# CTRL_MODULE_CORE register map
Vendor: Texas Instruments
Registers are 32-bit, access per field, reset 0x0 unless marked. A register's access mark holds for its fields unless they carry their own. Offsets are as the file gives them; [hi:lo] are bit positions; {n}, {i} and the like mark numbered series; 'fields as' and 'values as' point back to an identical list.

## CTRL_MODULE_CORE (part 2 of 12)
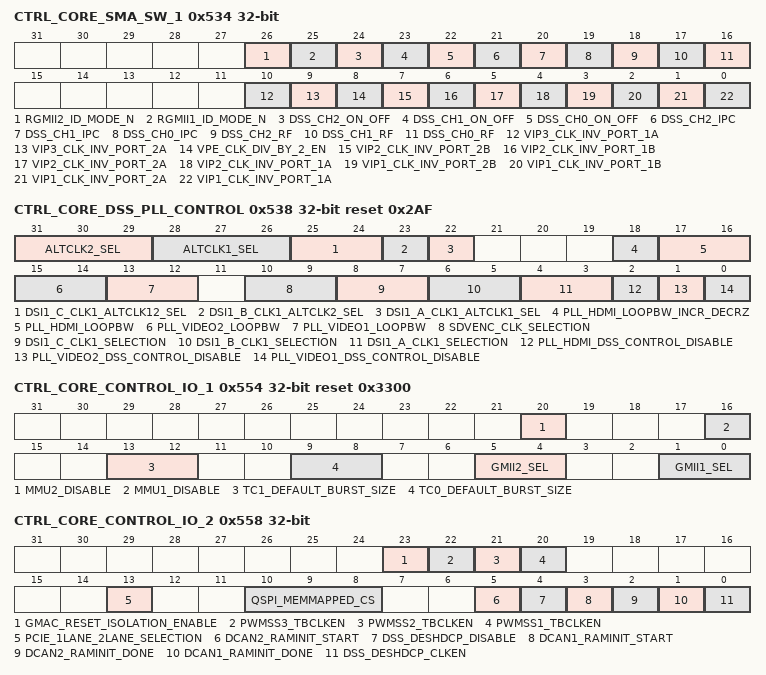
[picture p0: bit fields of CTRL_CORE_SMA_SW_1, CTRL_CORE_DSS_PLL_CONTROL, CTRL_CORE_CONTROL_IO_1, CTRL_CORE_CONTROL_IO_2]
0x534 CTRL_CORE_SMA_SW_1 — OCP Spare Register
  [26] RGMII2_ID_MODE_N rw — Ethernet RGMII port 2 internal delay on transmit 0x0: Internal delay enabled 0x1: Internal delay disabled
  [25] RGMII1_ID_MODE_N rw — Ethernet RGMII port 1 internal delay on transmit 0x0: Internal delay enabled 0x1: Internal delay disabled
  [24] DSS_CH2_ON_OFF rw — DSS Channel 2 Pixel clock control On/Off 0x0: HSYNC and VSYNC are driven on opposite edges of pixel clock than pixel data 0x1: HSYNC and VSYNC are driven according to bit DSS_CH2_RF
  [23] DSS_CH1_ON_OFF rw — DSS Channel 1 Pixel clock control On/Off 0x0: HSYNC and VSYNC are driven on opposite edges of pixel clock than pixel data 0x1: HSYNC and VSYNC are driven according to bit DSS_CH1_RF
  [22] DSS_CH0_ON_OFF rw — DSS Channel 0 Pixel clock control On/Off 0x0: HSYNC and VSYNC are driven on opposite edges of pixel clock than pixel data 0x1: HSYNC and VSYNC are driven according to bit DSS_CH0_RF
  [21] DSS_CH2_IPC rw — DSS Channel 2 IPC control 0x0: Data is driven on the LCD data lines on the rising edge of the pixel clock 0x1: Data is driven on the LCD data lines on the falling edge of the pixel clock
  [20] DSS_CH1_IPC rw — DSS Channel 1 IPC control 0x0: Data is driven on the LCD data lines on the rising edge of the pixel clock 0x1: Data is driven on the LCD data lines on the falling edge of the pixel clock
  [19] DSS_CH0_IPC rw — DSS Channel 0 IPC control 0x0: Data is driven on the LCD data lines on the rising edge of the pixel clock 0x1: Data is driven on the LCD data lines on the falling edge of the pixel clock
  [18] DSS_CH2_RF rw — DSS Channel 2 Rise/Fall control 0x0: HSYNC and VSYNC are driven on falling edge of pixel clock (if bit DSS_CH2_ON_OFF set to 1) 0x1: HSYNC and VSYNC are driven on rising edge of pixel clock (if bit DSS_CH2_ON_OFF set to 1)
  [17] DSS_CH1_RF rw — DSS Channel 1 Rise/Fall control 0x0: HSYNC and VSYNC are driven on falling edge of pixel clock (if bit DSS_CH1_ON_OFF set to 1) 0x1: HSYNC and VSYNC are driven on rising edge of pixel clock (if bit DSS_CH1_ON_OFF set to 1)
  [16] DSS_CH0_RF rw — DSS Channel 0 Rise/Fall control 0x0: HSYNC and VSYNC are driven on falling edge of pixel clock (if bit DSS_CH0_ON_OFF set to 1) 0x1: HSYNC and VSYNC are driven on rising edge of pixel clock (if bit DSS_CH0_ON_OFF set to 1)
  [10] VIP3_CLK_INV_PORT_1A rw — VIP3 Slice 1 Clock inversion for Port A enable 0x0: clock inversion is disabled 0x1: clock inversion is enabled
  [9] VIP3_CLK_INV_PORT_2A rw — VIP3 Slice 0 Clock inversion for Port A enable 0x0: clock inversion is disabled 0x1: clock inversion is enabled
  [8] VPE_CLK_DIV_BY_2_EN rw — Selects alternative clock source for VPE. 0x0: Default clock source from DPLL_CORE is selected 0x1: Alternative clock source from DPLL_VIDEO1 is selected
  [7] VIP2_CLK_INV_PORT_2B rw — VIP2 Slice 1 Clock inversion for Port B enable 0x0: clock inversion is disabled 0x1: clock inversion is enabled
  [6] VIP2_CLK_INV_PORT_1B rw — VIP2 Slice 0 Clock inversion for Port B enable 0x0: clock inversion is disabled 0x1: clock inversion is enabled
  [5] VIP2_CLK_INV_PORT_2A rw — VIP2 Slice 1 Clock inversion for Port A enable 0x0: clock inversion is disabled 0x1: clock inversion is enabled
  [4] VIP2_CLK_INV_PORT_1A rw — VIP2 Slice 0 Clock inversion for Port A enable 0x0: clock inversion is disabled 0x1: clock inversion is enabled
  [3] VIP1_CLK_INV_PORT_2B rw — VIP1 Slice 1 Clock inversion for Port B enable 0x0: clock inversion is disabled 0x1: clock inversion is enabled
  [2] VIP1_CLK_INV_PORT_1B rw — VIP1 Slice 0 Clock inversion for Port B enable 0x0: clock inversion is disabled 0x1: clock inversion is enabled
  [1] VIP1_CLK_INV_PORT_2A rw — VIP1 Slice 1 Clock inversion for Port A enable 0x0: clock inversion is disabled 0x1: clock inversion is enabled
  [0] VIP1_CLK_INV_PORT_1A rw — VIP1 Slice 0 Clock inversion for Port A enable 0x0: clock inversion is disabled 0x1: clock inversion is enabled
0x538 CTRL_CORE_DSS_PLL_CONTROL rw reset 0x2AF — DSS PLLs Mux control register
  [31:29] ALTCLK2_SEL — Alternative clock selection for DSI1_B_CLK1, DSI1_C_CLK1 or both based on fields DSI1_B_CLK1_ALTCLK2_SEL and DSI1_C_CLK1_ALTCLK12_SEL. 0x0: wakeup0 pin 0x1: wakeup1 pin 0x2: vin1a_clk pin 0x3: vin1b_clk pin 0x4: DPLL_PCIE_REF 0x5: Reserved 0x6: DPLL_SATA 0x7: Reserved
  [28:26] ALTCLK1_SEL — Alternative clock selection for DSI1_A_CLK1, DSI1_C_CLK1 or both based on fields DSI1_A_CLK1_ALTCLK1_SEL and DSI1_C_CLK1_ALTCLK12_SEL. 0x0: wakeup0 pin 0x1: wakeup1 pin 0x2: vin1a_clk pin 0x3: vin1b_clk pin 0x4: DPLL_PCIE_REF 0x5: Reserved 0x6: DPLL_SATA 0x7: Reserved
  [25:24] DSI1_C_CLK1_ALTCLK12_SEL — DSI1_C_CLK1 alternative clock selection 0x0: Clock selection based on DSI1_C_CLK1_SELECTION 0x1: Clock selection based on ALTCLK1_SEL 0x2: Clock selection based on ALTCLK2_SEL 0x3: Reserved
  [23] DSI1_B_CLK1_ALTCLK2_SEL — DSI1_B_CLK1 alternative clock selection 0x0: Clock selection based on DSI1_B_CLK1_SELECTION 0x1: Clock selection based on ALTCLK2_SEL
  [22] DSI1_A_CLK1_ALTCLK1_SEL — DSI1_A_CLK1 alternative clock selection 0x0: Clock selection based on DSI1_A_CLK1_SELECTION 0x1: Clock selection based on ALTCLK1_SEL
  [18] PLL_HDMI_LOOPBW_INCR_DECRZ — 0x0: Decrease DPLL_HDMI loop bandwidth 0x1: Increase DPLL_HDMI loop bandwidth
  [17:16] PLL_HDMI_LOOPBW — DPLL_HDMI loop bandwidth mode If PLL_HDMI_LOOPBW_INCR_DECRZ = 0x0: 0x0: 1x Mode (Loop BW is REF_CLK/50) 0x1: 0.5x Mode (Loop BW is REF_CLK/100) 0x2: 0.25x Mode (Loop BW is REF_CLK/200) 0x3: 0.125x Mode (Loop BW is REF_CLK/400) If PLL_HDMI_LOOPBW_INCR_DECRZ = 0x1: 0x0: 1x Mode (Loop BW is REF_CLK/50) 0x1: 2x Mode (Loop BW is REF_CLK/25) 0x2: Reserved 0x3: Reserved
  [15:14] PLL_VIDEO2_LOOPBW — DPLL_VIDEO2 loop bandwidth mode 0x0: 1x Mode (Loop BW is REF_CLK/50) 0x1: 0.5x Mode (Loop BW is REF_CLK/100) 0x2: 0.25x Mode (Loop BW is REF_CLK/200) 0x3: 0.125x Mode (Loop BW is REF_CLK/400)
  [13:12] PLL_VIDEO1_LOOPBW — DPLL_VIDEO1 loop bandwidth mode 0x0: 1x Mode (Loop BW is REF_CLK/50) 0x1: 0.5x Mode (Loop BW is REF_CLK/100) 0x2: 0.25x Mode (Loop BW is REF_CLK/200) 0x3: 0.125x Mode (Loop BW is REF_CLK/400)
  [10:9] SDVENC_CLK_SELECTION — SDVENC_CLK mux configuration 0x0: HDMI_CLK 0x1: DPLL_VIDEO1_HSDIVIDER_clkout3
  [8:7] DSI1_C_CLK1_SELECTION — DSI1_C_CLK1 mux configuration 0x0: DPLL_VIDEO2 0x1: DPLL_VIDEO1 0x2: DPLL_HDMI
  [6:5] DSI1_B_CLK1_SELECTION — DSI1_B_CLK1 mux configuration 0x0: DPLL_VIDEO1 0x1: DPLL_VIDEO2 0x2: DPLL_HDMI 0x3: DPLL_ABE
  [4:3] DSI1_A_CLK1_SELECTION — DSI1_A_CLK1 mux configuration 0x0: DPLL_VIDEO1 0x1: DPLL_HDMI
  [2] PLL_HDMI_DSS_CONTROL_DISABLE — HDMI PLL disable 0x0: PLL enabled 0x1: PLL disabled
  [1] PLL_VIDEO2_DSS_CONTROL_DISABLE — VIDEO2 PLL disable 0x0: PLL enabled 0x1: PLL disabled
  [0] PLL_VIDEO1_DSS_CONTROL_DISABLE — VIDEO1 PLL disable 0x0: PLL enabled 0x1: PLL disabled
0x540 CTRL_CORE_MMR_LOCK_1 rw reset 0x1A1C8144 — Register to lock memory region starting at address offset 0x0000 0100 and ending at address offset 0x0000 079F
  [31:0] MMR_LOCK_1 — Lock value for region 0x0000 0100 to 0x0000 079F 0x1A1C8144 = lock value 0x2FF1AC2B = unlock value
0x544 CTRL_CORE_MMR_LOCK_2 rw reset 0xFDF45530 — Register to lock memory region starting at address offset 0x0000 07A0 and ending at address offset 0x0000 0D9F
  [31:0] MMR_LOCK_2 — Lock value for region 0x0000 07A0 to 0x0000 0D9F 0xFDF45530 = lock value 0xF757FDC0 = unlock value
0x548 CTRL_CORE_MMR_LOCK_3 rw reset 0x1AE6E320 — Register to lock memory region starting at address offset 0x0000 0DA0 and ending at address offset 0x0000 0FFF
  [31:0] MMR_LOCK_3 — Lock value for region 0x0000 0DA0 to 0x0000 0FFF 0x1AE6E320 = lock value 0xE2BC3A6D = unlock value
0x54C CTRL_CORE_MMR_LOCK_4 rw reset 0x2FFA927C — Register to lock memory region starting at address offset 0x0000 1000 and ending at address offset 0x0000 13FF
  [31:0] MMR_LOCK_4 — Lock value for region 0x0000 1000 to 0x0000 13FF 0x2FFA927C = lock value 0x1EBF131D = unlock value
0x550 CTRL_CORE_MMR_LOCK_5 rw reset 0x143F832C — Register to lock memory region starting at address offset 0x0000 1400 and ending at address offset 0x0000 1FFF
  [31:0] MMR_LOCK_5 — Lock value for region 0x0000 1400 to 0x0000 1FFF 0x143F832C = lock value 0x6F361E05 = unlock value
0x554 CTRL_CORE_CONTROL_IO_1 reset 0x3300 — Register to configure some IP level signals
  [20] MMU2_DISABLE rw — MMU2 DISABLE setting
  [16] MMU1_DISABLE rw — MMU1 DISABLE setting
  [13:12] TC1_DEFAULT_BURST_SIZE rw — EDMA TC1 Default Burst Size (DBS) setting 0x0: 16 byte burst 0x1: 32 byte burst 0x2: 64 byte burst 0x3: 128 byte burst
  [9:8] TC0_DEFAULT_BURST_SIZE rw — EDMA TC0 Default Burst Size (DBS) setting 0x0: 16 byte burst 0x1: 32 byte burst 0x2: 64 byte burst 0x3: 128 byte burst
  [5:4] GMII2_SEL rw — GMII2 selection setting 0x0: GMII/MII 0x1: RMII 0x2: RGMII 0x3: Reserved
  [1:0] GMII1_SEL rw — GMII1 selection setting 0x0: GMII/MII 0x1: RMII 0x2: RGMII 0x3: Reserved
0x558 CTRL_CORE_CONTROL_IO_2 — Register to configure some IP level signals
  [23] GMAC_RESET_ISOLATION_ENABLE rw — Reset isolation enable setting 0x0 = Reset is not isolated 0x1 = Reset is isolated
  [22] PWMSS3_TBCLKEN rw — PWMSS3 CLOCK ENABLE setting
  [21] PWMSS2_TBCLKEN rw — PWMSS2 CLOCK ENABLE setting
  [20] PWMSS1_TBCLKEN rw — PWMSS1 CLOCK ENABLE setting
  [13] PCIE_1LANE_2LANE_SELECTION rw — Reserved
  [10:8] QSPI_MEMMAPPED_CS rw — QSPI CS MAPPING setting. 0x0: The QSPI configuration registers are accessed 0x1: An external device connected to CS0 is accessed 0x2: An external device connected to CS1 is accessed 0x3: An external device connected to CS2 is accessed 0x4-0x7: An external device connected to CS3 is accessed
  [5] DCAN2_RAMINIT_START rw — DCAN2 RAM INIT START setting To initialize DCAN2 RAM, the bit should be set to 0x1. It is not auto cleared by hardware. Note: If DCAN RAMINIT sequence needs to be redone, this bit should be first cleared and then set again.
  [4] DSS_DESHDCP_DISABLE rw — DSS DESHDCP DISABLE setting
  [3] DCAN1_RAMINIT_START rw — DCAN1 RAM INIT START setting To initialize DCAN1 RAM, the bit should be set to 0x1. It is not auto cleared by hardware. Note: If DCAN RAMINIT sequence needs to be redone, this bit should be first cleared and then set again.
  [2] DCAN2_RAMINIT_DONE rw — DCAN2 RAM INIT DONE status
  [1] DCAN1_RAMINIT_DONE rw — DCAN1 RAM INIT DONE status
  [0] DSS_DESHDCP_CLKEN rw — DSS DESHDCP CLOCK ENABLE setting
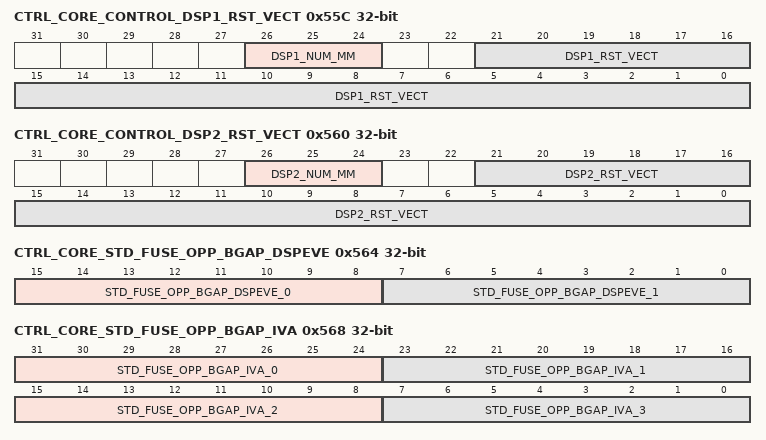
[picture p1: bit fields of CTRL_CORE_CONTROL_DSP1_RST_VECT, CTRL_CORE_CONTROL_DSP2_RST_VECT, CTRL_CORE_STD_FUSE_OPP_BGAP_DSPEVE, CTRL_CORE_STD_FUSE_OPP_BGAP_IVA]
0x55C CTRL_CORE_CONTROL_DSP1_RST_VECT — Register for storing DSP1 reset vector
  [26:24] DSP1_NUM_MM rw — Number of DSP instances in the SoC 0x1 = 1 0x2 = 2
  [21:0] DSP1_RST_VECT rw — DSP1 reset vector address
0x560 CTRL_CORE_CONTROL_DSP2_RST_VECT — Register for storing DSP2 reset vector
  [26:24] DSP2_NUM_MM rw — Number of DSP instances in the SoC 0x1 = 1 0x2 = 2
  [21:0] DSP2_RST_VECT rw — DSP2 reset vector address
0x564 CTRL_CORE_STD_FUSE_OPP_BGAP_DSPEVE ro reset not defined — Trim values for DSPEVE associated bandgap. Contains TI Internal information, not intended for application use.
  [15:8] STD_FUSE_OPP_BGAP_DSPEVE_0 — Trim values for DSPEVE associated bandgap. Contains TI Internal information, not intended for application use.
  [7:0] STD_FUSE_OPP_BGAP_DSPEVE_1 — Trim values for DSPEVE associated bandgap. Contains TI Internal information, not intended for application use.
0x568 CTRL_CORE_STD_FUSE_OPP_BGAP_IVA ro reset not defined — Trim values for IVA associated temperature sensor and bandgap. Contains TI Internal information, not intended for application use.
  [31-8n:24-8n] STD_FUSE_OPP_BGAP_IVA_{n} (n=0..3) — Trim values for IVA associated temperature sensor and bandgap. Contains TI Internal information, not intended for application use.
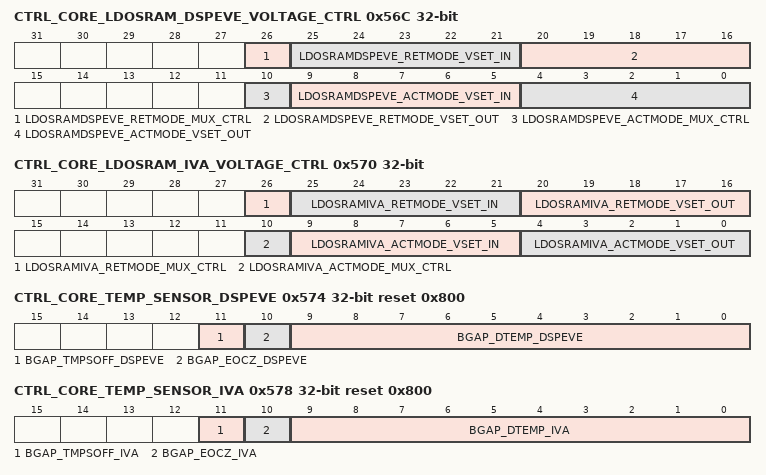
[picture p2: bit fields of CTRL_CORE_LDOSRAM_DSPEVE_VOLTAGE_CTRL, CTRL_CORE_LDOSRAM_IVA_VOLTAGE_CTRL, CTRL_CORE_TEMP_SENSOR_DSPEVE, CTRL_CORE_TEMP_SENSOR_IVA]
0x56C CTRL_CORE_LDOSRAM_DSPEVE_VOLTAGE_CTRL — DSPEVE SRAM LDO Control register
  [26] LDOSRAMDSPEVE_RETMODE_MUX_CTRL rw — Override control of EFUSE Retention Mode Voltage value
    0=EFUSE (eFuse value is used); 1=OCP (Override value is used)
  [25:21] LDOSRAMDSPEVE_RETMODE_VSET_IN ro — EFUSE Retention Mode Voltage value (vset[9:5])
  [20:16] LDOSRAMDSPEVE_RETMODE_VSET_OUT rw — Override value for Retention Mode Voltage
  [10] LDOSRAMDSPEVE_ACTMODE_MUX_CTRL rw — Override control of EFUSE Active Mode Voltage value
    values as LDOSRAMDSPEVE_RETMODE_MUX_CTRL
  [9:5] LDOSRAMDSPEVE_ACTMODE_VSET_IN ro — EFUSE Active Mode Voltage value (vset[4:0])
  [4:0] LDOSRAMDSPEVE_ACTMODE_VSET_OUT rw — Override value for Active Mode Voltage value
0x570 CTRL_CORE_LDOSRAM_IVA_VOLTAGE_CTRL — IVA SRAM LDO Control register
  [26] LDOSRAMIVA_RETMODE_MUX_CTRL rw — Override control of EFUSE Retention Mode Voltage value
    values as CTRL_CORE_LDOSRAM_DSPEVE_VOLTAGE_CTRL.LDOSRAMDSPEVE_RETMODE_MUX_CTRL
  [25:21] LDOSRAMIVA_RETMODE_VSET_IN ro — EFUSE Retention Mode Voltage value (vset[9:5])
  [20:16] LDOSRAMIVA_RETMODE_VSET_OUT rw — Override value for Retention Mode Voltage
  [10] LDOSRAMIVA_ACTMODE_MUX_CTRL rw — Override control of EFUSE Active Mode Voltage value
    values as CTRL_CORE_LDOSRAM_DSPEVE_VOLTAGE_CTRL.LDOSRAMDSPEVE_RETMODE_MUX_CTRL
  [9:5] LDOSRAMIVA_ACTMODE_VSET_IN ro — EFUSE Active Mode Voltage value (vset[4:0])
  [4:0] LDOSRAMIVA_ACTMODE_VSET_OUT rw — Override value for Active Mode Voltage value
0x574 CTRL_CORE_TEMP_SENSOR_DSPEVE ro reset 0x800 — Control VBGAPTS temperature sensor and thermal comparator shutdown register
  [11] BGAP_TMPSOFF_DSPEVE — This bit indicates the temperature sensor state.
  [10] BGAP_EOCZ_DSPEVE — ADC End of Conversion. Active low, when BGAP_DTEMP_DSPEVE is valid.
  [9:0] BGAP_DTEMP_DSPEVE — Temperature data from the ADC. Valid if EOCZ is low.
0x578 CTRL_CORE_TEMP_SENSOR_IVA ro reset 0x800 — Control VBGAPTS temperature sensor and thermal comparator shutdown register
  [11] BGAP_TMPSOFF_IVA — This bit indicates the temperature sensor state.
  [10] BGAP_EOCZ_IVA — ADC End of Conversion. Active low, when BGAP_DTEMP_IVA is valid.
  [9:0] BGAP_DTEMP_IVA — Temperature data from the ADC. Valid if EOCZ is low.
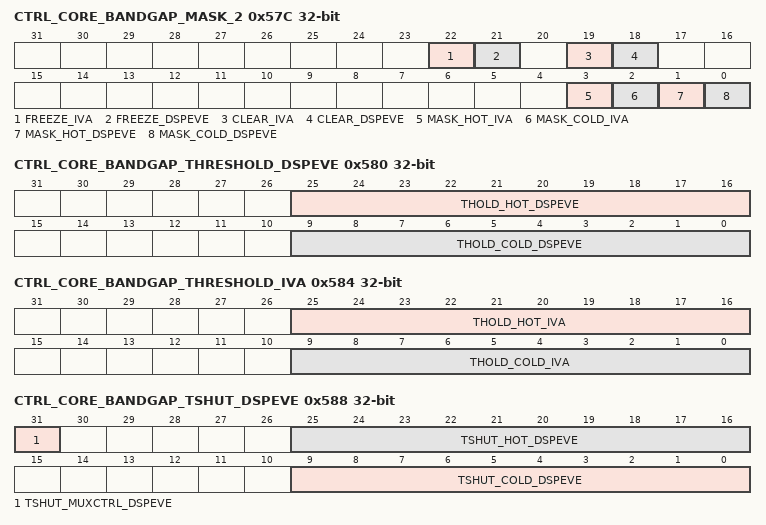
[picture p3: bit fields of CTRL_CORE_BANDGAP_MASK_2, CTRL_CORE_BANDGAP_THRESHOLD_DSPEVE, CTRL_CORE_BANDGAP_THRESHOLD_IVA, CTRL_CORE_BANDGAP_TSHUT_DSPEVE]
0x57C CTRL_CORE_BANDGAP_MASK_2 — bgap_mask
  [22] FREEZE_IVA rw — Freeze the FIFO IVA 0x0 = No operation 0x1 = Freeze the FIFO
  [21] FREEZE_DSPEVE rw — Freeze the FIFO DSPEVE 0x0 = No operation 0x1 = Freeze the FIFO
  [19] CLEAR_IVA rw — Reset the FIFO IVA 0x0 = No operation 0x1 = Reset the FIFO
  [18] CLEAR_DSPEVE rw — Reset the FIFO DSPEVE 0x0 = No operation 0x1 = Reset the FIFO
  [3] MASK_HOT_IVA rw — Mask for hot event IVA 0x0 = hot event is masked 0x1 = hot event is not masked
  [2] MASK_COLD_IVA rw — Mask for cold event IVA 0x0 = cold event is masked 0x1 = cold event is not masked
  [1] MASK_HOT_DSPEVE rw — Mask for hot event DSPEVE 0x0 = hot event is masked 0x1 = hot event is not masked
  [0] MASK_COLD_DSPEVE rw — Mask for cold event DSPEVE 0x0 = cold event is masked 0x1 = cold event is not masked
0x580 CTRL_CORE_BANDGAP_THRESHOLD_DSPEVE — BGAP THRESHOLD DSPEVE
  [25:16] THOLD_HOT_DSPEVE rw — Value for the high temperature threshold. The values for loading this bit field are listed in.
  [9:0] THOLD_COLD_DSPEVE rw — Value for the low temperature threshold. The values for loading this bit field are listed in.
0x584 CTRL_CORE_BANDGAP_THRESHOLD_IVA — BGAP THRESHOLD IVA
  [25:16] THOLD_HOT_IVA rw — Value for the high temperature threshold. The values for loading this bit field are listed in.
  [9:0] THOLD_COLD_IVA rw — Value for the low temperature threshold. The values for loading this bit field are listed in.
0x588 CTRL_CORE_BANDGAP_TSHUT_DSPEVE — BGAP TSHUT THRESHOLD IVA
  [31] TSHUT_MUXCTRL_DSPEVE rw — Writing a ‘1’ to this field allows SW to override the TSHUT_HOT and TSHUT_COLD values that are set by default in efuse.
  [25:16] TSHUT_HOT_DSPEVE rw — Controls the TSHUT_HOT reset threshold, which protects the device from thermal runaway and potential device damage. The register defaults to 123°C.
  [9:0] TSHUT_COLD_DSPEVE rw — Controls the TSHUT_COLD reset threshold, which is the limit where the TSHUT comparator releases the device from reset after cooling from a TSHUT condition. The register defaults to 105°C.
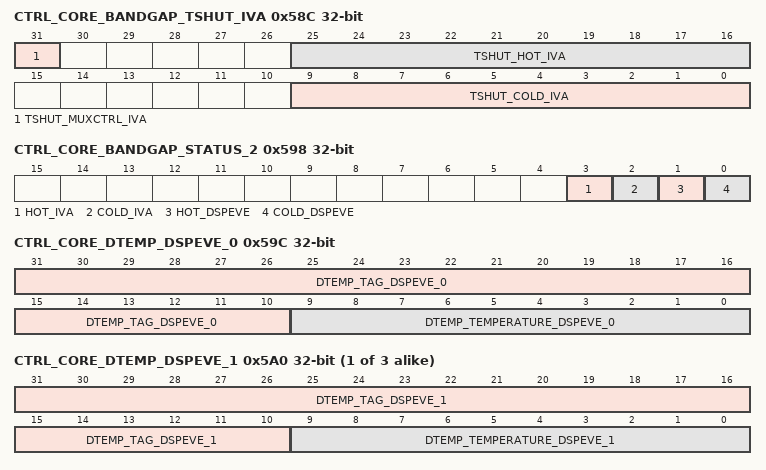
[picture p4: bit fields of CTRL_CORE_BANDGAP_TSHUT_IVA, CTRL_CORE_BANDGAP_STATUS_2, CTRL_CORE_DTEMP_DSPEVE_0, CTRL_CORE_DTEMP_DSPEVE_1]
0x58C CTRL_CORE_BANDGAP_TSHUT_IVA — BGAP TSHUT THRESHOLD IVA
  [31] TSHUT_MUXCTRL_IVA rw — Writing a ‘1’ to this field allows SW to override the TSHUT_HOT and TSHUT_COLD values that are set by default in efuse
  [25:16] TSHUT_HOT_IVA rw — Controls the TSHUT_HOT reset threshold, which protects the device from thermal runaway and potential device damage. The register defaults to 123°C.
  [9:0] TSHUT_COLD_IVA rw — tshut value cold Controls the TSHUT_COLD reset threshold, which is the limit where the TSHUT comparator releases the device from reset after cooling from a TSHUT condition. The register defaults to 105°C.
0x598 CTRL_CORE_BANDGAP_STATUS_2 ro — BGAP STATUS
  [3] HOT_IVA — Event for hot temperature iva bandgap when '1' 0x0 = event not detected 0x1 = event detected
  [2] COLD_IVA — Event for cold temperature iva bandgap when '1' 0x0 = event not detected 0x1 = event detected
  [1] HOT_DSPEVE — Event for hot temperature dspeve bandgap when '1' 0x0 = event not detected 0x1 = event detected
  [0] COLD_DSPEVE — Event for cold temperature dspeve bandgap when '1' 0x0 = event not detected 0x1 = event detected
0x59C CTRL_CORE_DTEMP_DSPEVE_0 ro — TAGGED TEMPERATURE DSPEVE DOMAIN. Most recent sample
  [31:10] DTEMP_TAG_DSPEVE_0 — tag. Indicate number of times in the bgap state machine.
  [9:0] DTEMP_TEMPERATURE_DSPEVE_0 — temperature
{0x59C+4i} CTRL_CORE_DTEMP_DSPEVE_{i} ro (i=1..3) — TAGGED TEMPERATURE DSPEVE DOMAIN
  [31:10] DTEMP_TAG_DSPEVE_{i} — tag. Indicate number of times in the bgap state machine.
  [9:0] DTEMP_TEMPERATURE_DSPEVE_{i} — temperature
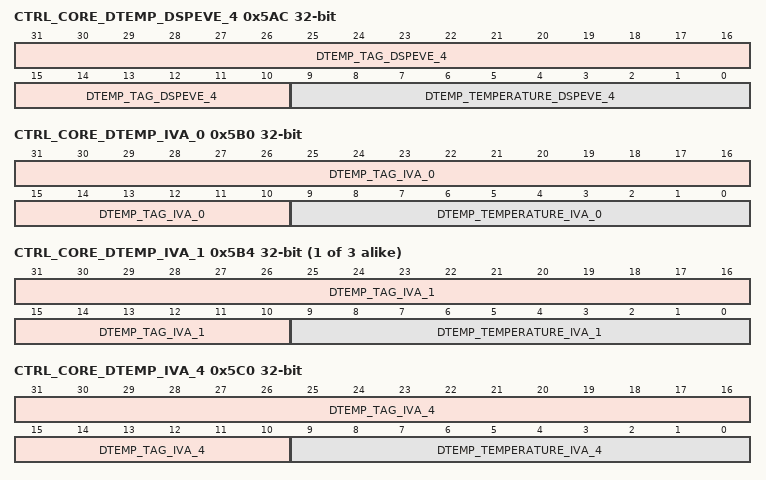
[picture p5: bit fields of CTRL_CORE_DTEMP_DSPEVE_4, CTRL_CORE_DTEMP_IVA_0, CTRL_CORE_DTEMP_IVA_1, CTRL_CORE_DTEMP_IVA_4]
0x5AC CTRL_CORE_DTEMP_DSPEVE_4 ro — TAGGED TEMPERATURE DSPEVE DOMAIN. Oldest sample
  [31:10] DTEMP_TAG_DSPEVE_4 — tag. Indicate number of times in the bgap state machine.
  [9:0] DTEMP_TEMPERATURE_DSPEVE_4 — temperature
0x5B0 CTRL_CORE_DTEMP_IVA_0 ro — TAGGED TEMPERATURE IVA DOMAIN. Most recent sample
  [31:10] DTEMP_TAG_IVA_0 — tag. Indicate number of times in the bgap state machine.
  [9:0] DTEMP_TEMPERATURE_IVA_0 — temperature
{0x5B0+4i} CTRL_CORE_DTEMP_IVA_{i} ro (i=1..3) — TAGGED TEMPERATURE IVA DOMAIN
  [31:10] DTEMP_TAG_IVA_{i} — tag. Indicate number of times in the bgap state machine.
  [9:0] DTEMP_TEMPERATURE_IVA_{i} — temperature
0x5C0 CTRL_CORE_DTEMP_IVA_4 ro — TAGGED TEMPERATURE IVA DOMAIN. Oldest sample
  [31:10] DTEMP_TAG_IVA_4 — tag. Indicate number of times in the bgap state machine.
  [9:0] DTEMP_TEMPERATURE_IVA_4 — temperature
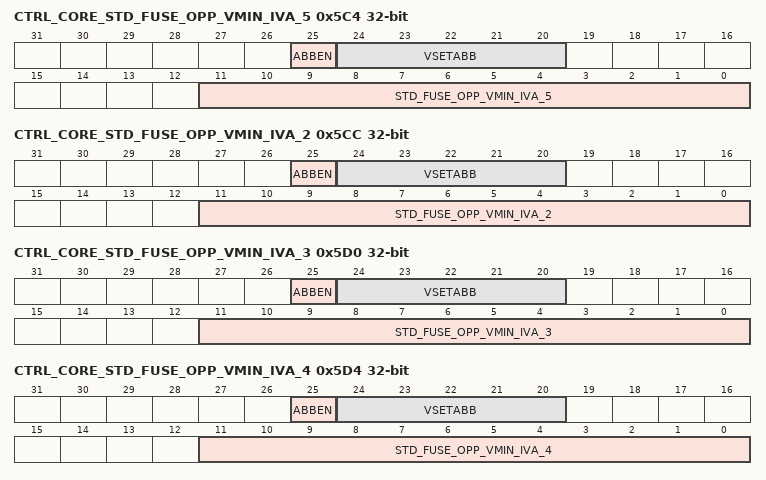
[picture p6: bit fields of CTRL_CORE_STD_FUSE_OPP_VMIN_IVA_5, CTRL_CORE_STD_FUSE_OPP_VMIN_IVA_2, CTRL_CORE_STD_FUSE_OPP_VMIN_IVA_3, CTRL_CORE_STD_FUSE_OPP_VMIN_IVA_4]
0x5C4 CTRL_CORE_STD_FUSE_OPP_VMIN_IVA_5 ro reset not defined — This register contains the AVS Class 0 voltage value for the vdd_iva voltage rail when running at OPP_PLUS. This register also stores information about ABB configuration for that OPP.
  [25] ABBEN
    0=ABB_disabled (ABB is disabled); 1=ABB_enabled (ABB is enabled)
  [24:20] VSETABB — This bit field shows the ABB LDO target value for OPP_PLUS which has to be written to theCTRL_CORE_LDOVBB_IVA_VOLTAGE_CTRL [4:0] LDOVBBIVA_FBB_VSET_OUT bit field, if ABB is enabled.
  [11:0] STD_FUSE_OPP_VMIN_IVA_5 — AVS Class 0 voltage value for the vdd_iva voltage rail when running at OPP_PLUS. To get the actual value in mV, the value read from this bit field must be converted to decimal value.
0x5CC CTRL_CORE_STD_FUSE_OPP_VMIN_IVA_2 ro reset not defined — This register contains the AVS Class 0 voltage value for the vdd_iva voltage rail when running at OPP_NOM. This register also stores information about ABB configuration for that OPP.
  [25] ABBEN
    values as CTRL_CORE_STD_FUSE_OPP_VMIN_IVA_5.ABBEN
  [24:20] VSETABB — This bit field shows the ABB LDO target value for OPP_NOM which has to be written to theCTRL_CORE_LDOVBB_IVA_VOLTAGE_CTRL [4:0] LDOVBBIVA_FBB_VSET_OUT bit field, if ABB is enabled.
  [11:0] STD_FUSE_OPP_VMIN_IVA_2 — AVS Class 0 voltage value for the vdd_iva voltage rail when running at OPP_NOM. To get the actual value in mV, the value read from this bit field must be converted to decimal value.
0x5D0 CTRL_CORE_STD_FUSE_OPP_VMIN_IVA_3 ro reset not defined — This register contains the AVS Class 0 voltage value for the vdd_iva voltage rail when running at OPP_OD. This register also stores information about ABB configuration for that OPP.
  [25] ABBEN
    values as CTRL_CORE_STD_FUSE_OPP_VMIN_IVA_5.ABBEN
  [24:20] VSETABB — This bit field shows the ABB LDO target value for OPP_OD which has to be written to theCTRL_CORE_LDOVBB_IVA_VOLTAGE_CTRL [4:0] LDOVBBIVA_FBB_VSET_OUT bit field, if ABB is enabled.
  [11:0] STD_FUSE_OPP_VMIN_IVA_3 — AVS Class 0 voltage value for the vdd_iva voltage rail when running at OPP_OD. To get the actual value in mV, the value read from this bit field must be converted to decimal value.
0x5D4 CTRL_CORE_STD_FUSE_OPP_VMIN_IVA_4 ro reset not defined — This register contains the AVS Class 0 voltage value for the vdd_iva voltage rail when running at OPP_HIGH. This register also stores information about ABB configuration for that OPP.
  [25] ABBEN
    values as CTRL_CORE_STD_FUSE_OPP_VMIN_IVA_5.ABBEN
  [24:20] VSETABB — This bit field shows the ABB LDO target value for OPP_HIGH which has to be written to theCTRL_CORE_LDOVBB_IVA_VOLTAGE_CTRL [4:0] LDOVBBIVA_FBB_VSET_OUT bit field, if ABB is enabled.
  [11:0] STD_FUSE_OPP_VMIN_IVA_4 — AVS Class 0 voltage value for the vdd_iva voltage rail when running at OPP_HIGH. To get the actual value in mV, the value read from this bit field must be converted to decimal value.
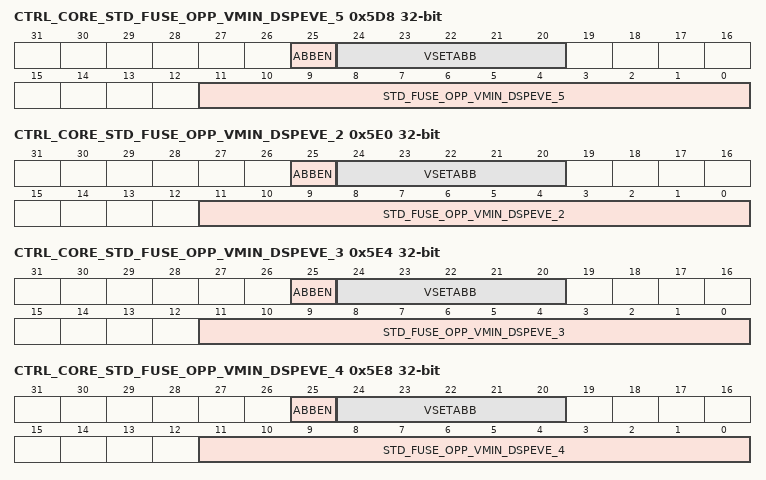
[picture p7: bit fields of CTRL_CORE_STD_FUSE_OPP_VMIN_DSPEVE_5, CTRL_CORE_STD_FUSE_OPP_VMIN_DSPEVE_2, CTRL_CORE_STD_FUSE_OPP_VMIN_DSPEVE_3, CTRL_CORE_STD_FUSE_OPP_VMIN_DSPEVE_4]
0x5D8 CTRL_CORE_STD_FUSE_OPP_VMIN_DSPEVE_5 ro reset not defined — This register contains the AVS Class 0 voltage value for the vdd_dspeve voltage rail when running at OPP_PLUS. This register also stores information about ABB configuration for that OPP.
  [25] ABBEN
    values as CTRL_CORE_STD_FUSE_OPP_VMIN_IVA_5.ABBEN
  [24:20] VSETABB — This bit field shows the ABB LDO target value for OPP_PLUS which has to be written to theCTRL_CORE_LDOVBB_DSPEVE_VOLTAGE_CTRL [4:0] LDOVBBDSPEVE_FBB_VSET_OUT bit field, if ABB is enabled.
  [11:0] STD_FUSE_OPP_VMIN_DSPEVE_5 — AVS Class 0 voltage value for the vdd_dspeve voltage rail when running at OPP_PLUS. To get the actual value in mV, the value read from this bit field must be converted to decimal value.
0x5E0 CTRL_CORE_STD_FUSE_OPP_VMIN_DSPEVE_2 ro reset not defined — This register contains the AVS Class 0 voltage value for the vdd_dspeve voltage rail when running at OPP_NOM. This register also stores information about ABB configuration for that OPP.
  [25] ABBEN
    values as CTRL_CORE_STD_FUSE_OPP_VMIN_IVA_5.ABBEN
  [24:20] VSETABB — This bit field shows the ABB LDO target value for OPP_NOM which has to be written to theCTRL_CORE_LDOVBB_DSPEVE_VOLTAGE_CTRL [4:0] LDOVBBDSPEVE_FBB_VSET_OUT bit field, if ABB is enabled.
  [11:0] STD_FUSE_OPP_VMIN_DSPEVE_2 — AVS Class 0 voltage value for the vdd_dspeve voltage rail when running at OPP_NOM. To get the actual value in mV, the value read from this bit field must be converted to decimal value.
0x5E4 CTRL_CORE_STD_FUSE_OPP_VMIN_DSPEVE_3 ro reset not defined — This register contains the AVS Class 0 voltage value for the vdd_dspeve voltage rail when running at OPP_OD. This register also stores information about ABB configuration for that OPP.
  [25] ABBEN
    values as CTRL_CORE_STD_FUSE_OPP_VMIN_IVA_5.ABBEN
  [24:20] VSETABB — This bit field shows the ABB LDO target value for OPP_OD which has to be written to theCTRL_CORE_LDOVBB_DSPEVE_VOLTAGE_CTRL [4:0] LDOVBBDSPEVE_FBB_VSET_OUT bit field, if ABB is enabled.
  [11:0] STD_FUSE_OPP_VMIN_DSPEVE_3 — AVS Class 0 voltage value for the vdd_dspeve voltage rail when running at OPP_OD. To get the actual value in mV, the value read from this bit field must be converted to decimal value.
0x5E8 CTRL_CORE_STD_FUSE_OPP_VMIN_DSPEVE_4 ro reset not defined — This register contains the AVS Class 0 voltage value for the vdd_dspeve voltage rail when running at OPP_HIGH. This register also stores information about ABB configuration for that OPP.
  [25] ABBEN
    values as CTRL_CORE_STD_FUSE_OPP_VMIN_IVA_5.ABBEN
  [24:20] VSETABB — This bit field shows the ABB LDO target value for OPP_HIGH which has to be written to theCTRL_CORE_LDOVBB_DSPEVE_VOLTAGE_CTRL [4:0] LDOVBBDSPEVE_FBB_VSET_OUT bit field, if ABB is enabled.
  [11:0] STD_FUSE_OPP_VMIN_DSPEVE_4 — AVS Class 0 voltage value for the vdd_dspeve voltage rail when running at OPP_HIGH. To get the actual value in mV, the value read from this bit field must be converted to decimal value.
0x5F4 CTRL_CORE_STD_FUSE_OPP_VMIN_CORE_2 ro reset not defined — This register contains the AVS Class 0 voltage value for the vdd voltage rail when running at OPP_NOM.
  [11:0] STD_FUSE_OPP_VMIN_CORE_2 — AVS Class 0 voltage value for the vdd voltage rail when running at OPP_NOM. To get the actual value in mV, the value read from this bit field must be converted to decimal value.
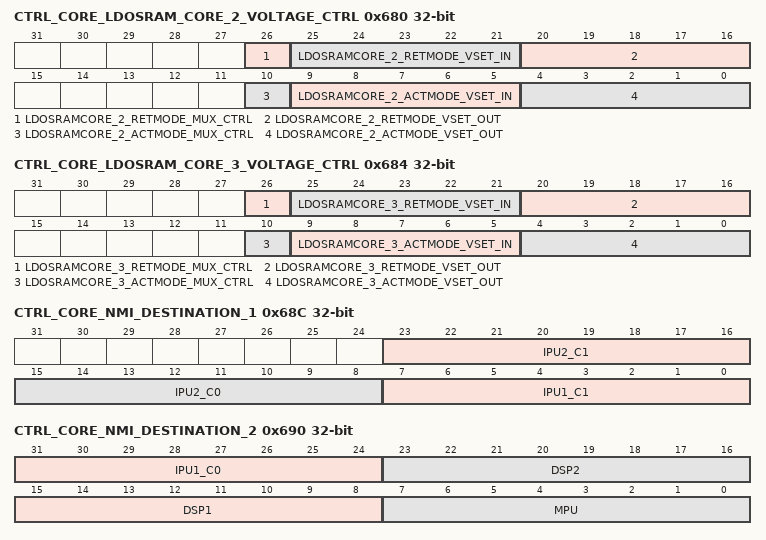
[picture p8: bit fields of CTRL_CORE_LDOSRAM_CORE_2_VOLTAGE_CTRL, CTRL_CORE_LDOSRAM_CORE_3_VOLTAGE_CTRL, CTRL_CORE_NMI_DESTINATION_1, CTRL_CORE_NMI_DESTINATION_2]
0x680 CTRL_CORE_LDOSRAM_CORE_2_VOLTAGE_CTRL — CORE 2nd SRAM LDO Control register
  [26] LDOSRAMCORE_2_RETMODE_MUX_CTRL rw — Override control of EFUSE Retention Mode Voltage value
    values as CTRL_CORE_LDOSRAM_DSPEVE_VOLTAGE_CTRL.LDOSRAMDSPEVE_RETMODE_MUX_CTRL
  [25:21] LDOSRAMCORE_2_RETMODE_VSET_IN ro — EFUSE Retention Mode Voltage value (vset[9:5])
  [20:16] LDOSRAMCORE_2_RETMODE_VSET_OUT rw — Override value for Retention Mode Voltage
  [10] LDOSRAMCORE_2_ACTMODE_MUX_CTRL rw — Override control of EFUSE Active Mode Voltage value
    values as CTRL_CORE_LDOSRAM_DSPEVE_VOLTAGE_CTRL.LDOSRAMDSPEVE_RETMODE_MUX_CTRL
  [9:5] LDOSRAMCORE_2_ACTMODE_VSET_IN ro — EFUSE Active Mode Voltage value (vset[4:0])
  [4:0] LDOSRAMCORE_2_ACTMODE_VSET_OUT rw — Override value for Active Mode Voltage value
0x684 CTRL_CORE_LDOSRAM_CORE_3_VOLTAGE_CTRL — CORE 3rd SRAM LDO Control register
  [26] LDOSRAMCORE_3_RETMODE_MUX_CTRL rw — Override control of EFUSE Retention Mode Voltage value
    values as CTRL_CORE_LDOSRAM_DSPEVE_VOLTAGE_CTRL.LDOSRAMDSPEVE_RETMODE_MUX_CTRL
  [25:21] LDOSRAMCORE_3_RETMODE_VSET_IN ro — EFUSE Retention Mode Voltage value (vset[9:5])
  [20:16] LDOSRAMCORE_3_RETMODE_VSET_OUT rw — Override value for Retention Mode Voltage
  [10] LDOSRAMCORE_3_ACTMODE_MUX_CTRL rw — Override control of EFUSE Active Mode Voltage value
    values as CTRL_CORE_LDOSRAM_DSPEVE_VOLTAGE_CTRL.LDOSRAMDSPEVE_RETMODE_MUX_CTRL
  [9:5] LDOSRAMCORE_3_ACTMODE_VSET_IN ro — EFUSE Active Mode Voltage value (vset[4:0])
  [4:0] LDOSRAMCORE_3_ACTMODE_VSET_OUT rw — Override value for Active Mode Voltage value
0x68C CTRL_CORE_NMI_DESTINATION_1 rw — Register for routing NMI interrupt to respective cores
  [23:16] IPU2_C1 — Enable IPU2 CORE1 to receive the NMI interrupt 0x0 = NMI disabled 0x1 = NMI enabled
  [15:8] IPU2_C0 — Enable IPU2 CORE0 to receive the NMI interrupt 0x0 = NMI disabled 0x1 = NMI enabled
  [7:0] IPU1_C1 — Enable IPU1 CORE1 to receive the NMI interrupt 0x0 = NMI disabled 0x1 = NMI enabled
0x690 CTRL_CORE_NMI_DESTINATION_2 rw — Register for routing NMI interrupt to respective cores
  [31:24] IPU1_C0 — Enable IPU1 CORE0 to receive the NMI interrupt 0x0 = NMI disabled 0x1 = NMI enabled
  [23:16] DSP2 — Enable DSP2 to receive the NMI interrupt 0x0 = NMI disabled 0x1 = NMI enabled
  [15:8] DSP1 — Enable DSP1 to receive the NMI interrupt 0x0 = NMI disabled 0x1 = NMI enabled
  [7:0] MPU — Comes from Efuse (MPU_EN) 0x0 = NMI disabled 0x1 = NMI enabled
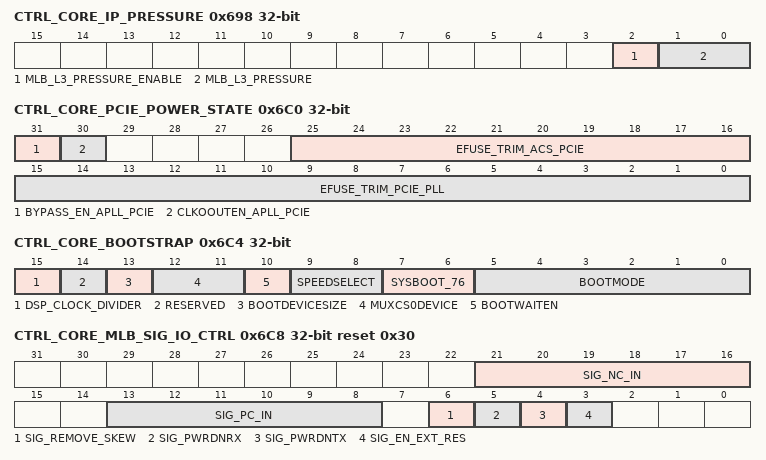
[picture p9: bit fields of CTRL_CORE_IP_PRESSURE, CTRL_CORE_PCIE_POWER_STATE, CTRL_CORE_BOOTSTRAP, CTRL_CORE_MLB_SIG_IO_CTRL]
0x698 CTRL_CORE_IP_PRESSURE — Register to override the L3 pressure setting for the MLB module.
  [2] MLB_L3_PRESSURE_ENABLE rw — Override enable for the MLB L3 pressure setting 0x0 = Overriding of the L3 pressure setting for the MLB module is disabled 0x1 = Overriding of the L3 pressure setting for the MLB module is enabled
  [1:0] MLB_L3_PRESSURE rw — MLB L3 pressure setting 0x0 = Lowest 0x3 = Highest
{0x6A0+4i} CTRL_CORE_STD_FUSE_OPP_VDD_DSPEVE_{i} ro (i=0..4) — Standard Fuse OPP VDD_DSPEVE [{32i+31}:{32i}]. Register shows part of the chip eFuse configuration on the OCP interface. Reading at the address of one of these registers provides a direct view into a part of the eFuse chain.
  [31:0] STD_FUSE_OPP_VDD_DSPEVE_{i}
0x6B4 CTRL_CORE_CUST_FUSE_SWRV_7 ro — Customer Fuse keys. SWRV [31:0] (16 bits upper Redundant field) [FIELD A]. Register shows part of the chip eFuse configuration on the OCP interface. Reading at the address of one of these registers provides a direct view into a part of the eFuse chain.
  [31:0] CUST_FUSE_SWRV_7
0x6B8 CTRL_CORE_STD_FUSE_CALIBRATION_OVERRIDE_VALUE_0 ro — Standard Fuse Calibration override value [31:0]. Register shows part of the chip eFuse configuration on the OCP interface. Reading at the address of one of these registers provides a direct view into a part of the eFuse chain.
  [31:0] STD_FUSE_CALIBRATION_OVERRIDE_VALUE_0
0x6BC CTRL_CORE_STD_FUSE_CALIBRATION_OVERRIDE_VALUE_1 ro — Standard Fuse Calibration override value [63:32]. Register shows part of the chip eFuse configuration on the OCP interface. Reading at the address of one of these registers provides a direct view into a part of the eFuse chain.
  [31:0] STD_FUSE_CALIBRATION_OVERRIDE_VALUE_1
0x6C0 CTRL_CORE_PCIE_POWER_STATE — Register to PCIe related controls
  [31] BYPASS_EN_APLL_PCIE rw — Bypass enable bit setting for APLL_PCIe
  [30] CLKOOUTEN_APLL_PCIE rw — Clock output enable bit setting for APLL_PCIe
  [25:16] EFUSE_TRIM_ACS_PCIE rw — MMR override capability for ACS_PCIe efuse trim bits
  [15:0] EFUSE_TRIM_PCIE_PLL rw — MMR override capability for PCIe PLL efuse trim bits
0x6C4 CTRL_CORE_BOOTSTRAP ro — Register to view all the sysboot settings
  [15] DSP_CLOCK_DIVIDER — Permanently disables the internal PU/PD resistors on pads gpmc_a[27:24, 22:19]. 0x0: Internal pull-down resistors are enabled 0x1: Internal pull-down resistors are permanently disabled
  [14] RESERVED — For proper device operation, a value of 0 is required on sysboot14
  [13] BOOTDEVICESIZE — Select the size of the flash device on CS0. 0x0: 8-bit 0x1: 16-bit
  [12:11] MUXCS0DEVICE — Select IC boot sequence to be executed from a multiplexed address and data device attached to CS0. 0x0: Non-muxed device attached 0x1: Addr-Data Mux device attached 0x2: Reserved 0x3: Reserved
  [10] BOOTWAITEN — Enable the monitoring on CS0 of the wait pin at IC reset release time for read accesses. 0x0: Wait pin is not monitored for read accesses 0x1: Wait pin is monitored for read accesses
  [9:8] SPEEDSELECT — Indicates the SYS_CLK1 frequency (from osc0). Note that the internal FUNC_32K_CLK is equal to SYS_CLK1/610, which is nominally 32.7869 kHz with 20 MHz clock. 0x0: Reserved 0x1: 20 MHz 0x2: 27 MHz 0x3: 19.2 MHz
  [7:6] SYSBOOT_76 — Sector offset for the location of the redundant SBL images in QSPI. 0x0: 64 KB offset 0x1: 128 KB offset 0x2: 256 KB offset 0x3: 512 KB offset
  [5:0] BOOTMODE — SYSBOOT mode
0x6C8 CTRL_CORE_MLB_SIG_IO_CTRL reset 0x30 — Register to set the MLB's SIG IO characteristics
  [21:16] SIG_NC_IN rw — efuse trim for Nmos impedance
  [13:8] SIG_PC_IN rw — efuse trim for Pmos impedance
  [6] SIG_REMOVE_SKEW rw — Adjust for skew generated by the receiver due to asymmetric inputs. 0x0: skew compensation is disabled 0x1: skew compensation is enabled
  [5] SIG_PWRDNRX rw — powerdown receiver, active high 0x0 = Powered ON 0x1 = Powered OFF
  [4] SIG_PWRDNTX rw — powerdown transmitter, active high 0x0 = Powered ON 0x1 = Powered OFF
  [3] SIG_EN_EXT_RES rw — disables internal resistors 0x0 = Disabled 0x1 = Enabled
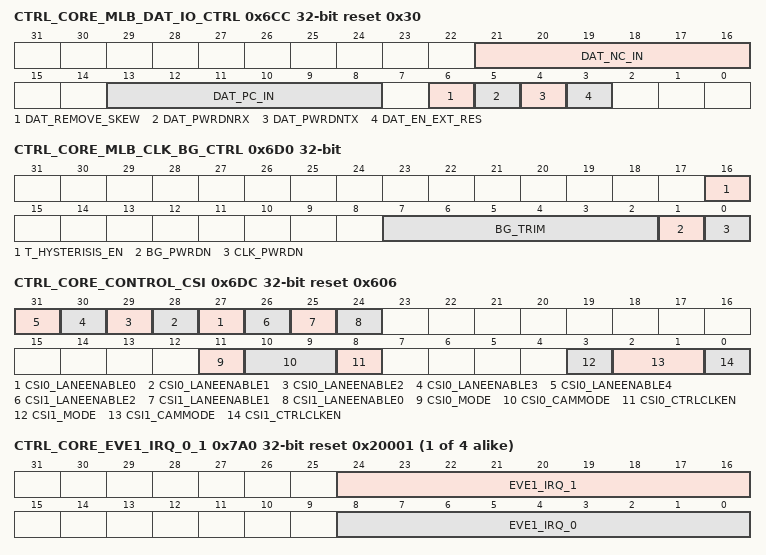
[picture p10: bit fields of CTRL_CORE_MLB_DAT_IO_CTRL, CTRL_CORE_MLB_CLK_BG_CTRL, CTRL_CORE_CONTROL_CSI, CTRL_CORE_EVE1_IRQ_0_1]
0x6CC CTRL_CORE_MLB_DAT_IO_CTRL reset 0x30 — Register to set the MLB's DAT IO characteristics
  [21:16] DAT_NC_IN rw — efuse trim for Nmos impedance
  [13:8] DAT_PC_IN rw — efuse trim for Pmos impedance
  [6] DAT_REMOVE_SKEW rw — Adjust for skew generated by the receiver due to asymmetric inputs. 0x0: skew compensation is disabled 0x1: skew compensation is enabled
  [5] DAT_PWRDNRX rw — powerdown receiver, active high 0x0 = Powered ON 0x1 = Powered OFF
  [4] DAT_PWRDNTX rw — powerdown transmitter, active high 0x0 = Powered ON 0x1 = Powered OFF
  [3] DAT_EN_EXT_RES rw — Enable/disable internal resistors 0x0 = Disabled 0x1 = Enabled
0x6D0 CTRL_CORE_MLB_CLK_BG_CTRL — Register to set the MLB's clock receiver IO and bandgap characteristics.
  [16] T_HYSTERISIS_EN rw — Hysterisis enable 0x0 = Disabled 0x1 = Enabled
  [7:2] BG_TRIM rw — Trim values for MLB bandgap
  [1] BG_PWRDN rw — MLB bandgap cell enable. 0x0 = The MLB bandgap cell is powered (enabled) 0x1 = The MLB bandgap cell is disabled
  [0] CLK_PWRDN rw — Enable the MLB differential clock receiver. 0x0 = MLB differential clock receiver is enabled 0x1 = MLB differential clock receiver is disabled
0x6DC CTRL_CORE_CONTROL_CSI reset 0x606 — CSI control register.
  [n+27] CSI0_LANEENABLE{n} rw (n=0..4) — csi0 camera lane enable 0x0: Lane module disabled 0x1: Lane module enabled
  [26] CSI1_LANEENABLE2 rw — csi1 camera lane enable 0x0: Lane module disabled 0x1: Lane module enabled
  [25] CSI1_LANEENABLE1 rw — csi1 camera lane enable 0x0: Lane module disabled 0x1: Lane module enabled
  [24] CSI1_LANEENABLE0 rw — csi1 camera lane enable 0x0: Lane module disabled 0x1: Lane module enabled
  [11] CSI0_MODE rw
  [10:9] CSI0_CAMMODE rw — csi0 camera mode 0x0: DPHY mode 0x1: Data/Strobe Transmission format 0x2: Data/Clock Transmission format 0x3: GPI mode
  [8] CSI0_CTRLCLKEN rw — csi0 camera clock enable control 0x0: Disable for CTRLCLK 0x1: Active high enable for CTRLCLK
  [3] CSI1_MODE rw
  [2:1] CSI1_CAMMODE rw — csi1 camera mode 0x0: DPHY mode 0x1: Data/Strobe Transmission format 0x2: Data/Clock Transmission format 0x3: GPI mode
  [0] CSI1_CTRLCLKEN rw — csi1 camera clock enable control 0x0: Disable for CTRLCLK 0x1: Active high enable for CTRLCLK
{0x790+0x10*i} CTRL_CORE_EVE{i}_IRQ_0_1 reset 0x20001 (i=1..4)
  [24:16] EVE{i}_IRQ_1 rw, [8:0] EVE{i}_IRQ_0 rw
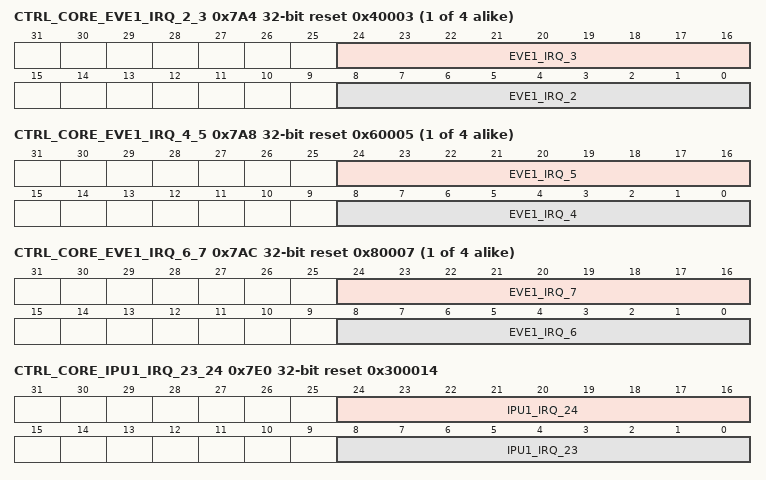
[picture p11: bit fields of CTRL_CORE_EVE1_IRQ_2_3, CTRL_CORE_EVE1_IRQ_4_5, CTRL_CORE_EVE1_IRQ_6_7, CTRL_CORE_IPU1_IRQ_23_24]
{0x794+0x10*i} CTRL_CORE_EVE{i}_IRQ_2_3 reset 0x40003 (i=1..4)
  [24:16] EVE{i}_IRQ_3 rw, [8:0] EVE{i}_IRQ_2 rw
{0x798+0x10*i} CTRL_CORE_EVE{i}_IRQ_4_5 reset 0x60005 (i=1..4)
  [24:16] EVE{i}_IRQ_5 rw, [8:0] EVE{i}_IRQ_4 rw
{0x79C+0x10*i} CTRL_CORE_EVE{i}_IRQ_6_7 reset 0x80007 (i=1..4)
  [24:16] EVE{i}_IRQ_7 rw, [8:0] EVE{i}_IRQ_6 rw
0x7E0 CTRL_CORE_IPU1_IRQ_23_24 reset 0x300014
  [24:16] IPU1_IRQ_24 rw, [8:0] IPU1_IRQ_23 rw
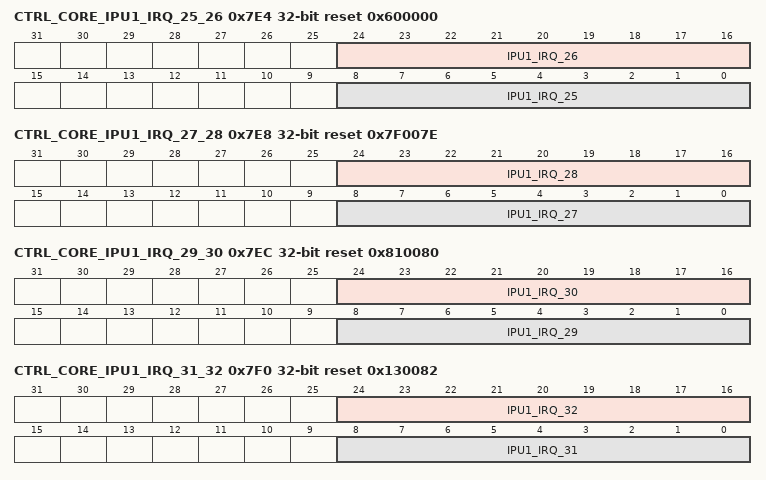
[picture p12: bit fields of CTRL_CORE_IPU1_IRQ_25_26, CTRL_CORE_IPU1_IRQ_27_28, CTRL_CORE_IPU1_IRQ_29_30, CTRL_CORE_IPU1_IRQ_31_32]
0x7E4 CTRL_CORE_IPU1_IRQ_25_26 reset 0x600000
  [24:16] IPU1_IRQ_26 rw, [8:0] IPU1_IRQ_25 rw
0x7E8 CTRL_CORE_IPU1_IRQ_27_28 reset 0x7F007E
  [24:16] IPU1_IRQ_28 rw, [8:0] IPU1_IRQ_27 rw
0x7EC CTRL_CORE_IPU1_IRQ_29_30 reset 0x810080
  [24:16] IPU1_IRQ_30 rw, [8:0] IPU1_IRQ_29 rw
0x7F0 CTRL_CORE_IPU1_IRQ_31_32 reset 0x130082
  [24:16] IPU1_IRQ_32 rw, [8:0] IPU1_IRQ_31 rw
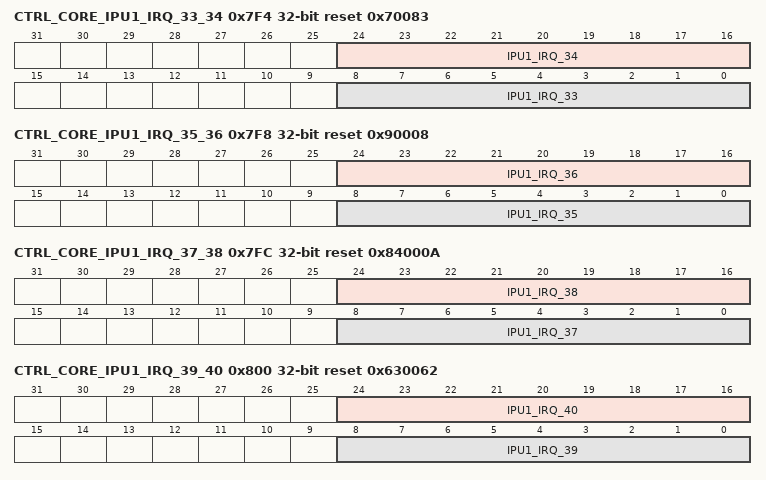
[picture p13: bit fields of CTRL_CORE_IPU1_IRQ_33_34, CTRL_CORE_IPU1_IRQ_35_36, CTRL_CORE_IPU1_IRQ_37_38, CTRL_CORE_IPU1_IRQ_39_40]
0x7F4 CTRL_CORE_IPU1_IRQ_33_34 reset 0x70083
  [24:16] IPU1_IRQ_34 rw, [8:0] IPU1_IRQ_33 rw
0x7F8 CTRL_CORE_IPU1_IRQ_35_36 reset 0x90008
  [24:16] IPU1_IRQ_36 rw, [8:0] IPU1_IRQ_35 rw
0x7FC CTRL_CORE_IPU1_IRQ_37_38 reset 0x84000A
  [24:16] IPU1_IRQ_38 rw, [8:0] IPU1_IRQ_37 rw
0x800 CTRL_CORE_IPU1_IRQ_39_40 reset 0x630062
  [24:16] IPU1_IRQ_40 rw, [8:0] IPU1_IRQ_39 rw
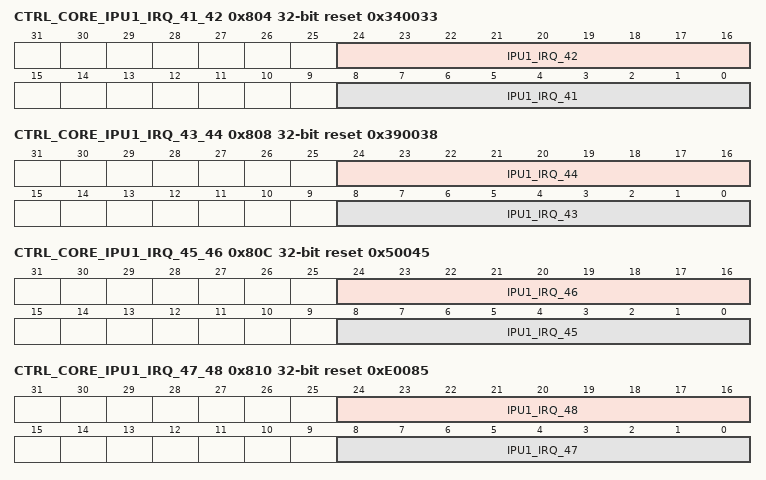
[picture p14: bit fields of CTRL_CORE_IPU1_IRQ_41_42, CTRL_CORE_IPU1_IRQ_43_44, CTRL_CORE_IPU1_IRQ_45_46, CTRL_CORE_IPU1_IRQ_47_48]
0x804 CTRL_CORE_IPU1_IRQ_41_42 reset 0x340033
  [24:16] IPU1_IRQ_42 rw, [8:0] IPU1_IRQ_41 rw
0x808 CTRL_CORE_IPU1_IRQ_43_44 reset 0x390038
  [24:16] IPU1_IRQ_44 rw, [8:0] IPU1_IRQ_43 rw
0x80C CTRL_CORE_IPU1_IRQ_45_46 reset 0x50045
  [24:16] IPU1_IRQ_46 rw, [8:0] IPU1_IRQ_45 rw
0x810 CTRL_CORE_IPU1_IRQ_47_48 reset 0xE0085
  [24:16] IPU1_IRQ_48 rw, [8:0] IPU1_IRQ_47 rw
0x814 CTRL_CORE_IPU1_IRQ_49_50 reset 0x860042
  [24:16] IPU1_IRQ_50 rw, [8:0] IPU1_IRQ_49 rw
0x818 CTRL_CORE_IPU1_IRQ_51_52 reset 0x190018
  [24:16] IPU1_IRQ_52 rw, [8:0] IPU1_IRQ_51 rw
0x81C CTRL_CORE_IPU1_IRQ_53_54 reset 0x230022
  [24:16] IPU1_IRQ_54 rw, [8:0] IPU1_IRQ_53 rw
0x820 CTRL_CORE_IPU1_IRQ_55_56 reset 0x2A0028
  [24:16] IPU1_IRQ_56 rw, [8:0] IPU1_IRQ_55 rw
0x824 CTRL_CORE_IPU1_IRQ_57_58 reset 0x3D003C
  [24:16] IPU1_IRQ_58 rw, [8:0] IPU1_IRQ_57 rw
0x828 CTRL_CORE_IPU1_IRQ_59_60 reset 0x32
  [24:16] IPU1_IRQ_60 rw, [8:0] IPU1_IRQ_59 rw
0x82C CTRL_CORE_IPU1_IRQ_61_62 reset 0x160000
  [24:16] IPU1_IRQ_62 rw, [8:0] IPU1_IRQ_61 rw
0x830 CTRL_CORE_IPU1_IRQ_63_64 reset 0x6C0053
  [24:16] IPU1_IRQ_64 rw, [8:0] IPU1_IRQ_63 rw
0x834 CTRL_CORE_IPU1_IRQ_65_66 reset 0x4E0078
  [24:16] IPU1_IRQ_66 rw, [8:0] IPU1_IRQ_65 rw
0x838 CTRL_CORE_IPU1_IRQ_67_68 reset 0x590051
  [24:16] IPU1_IRQ_68 rw, [8:0] IPU1_IRQ_67 rw
0x83C CTRL_CORE_IPU1_IRQ_69_70
  [24:16] IPU1_IRQ_70 rw, [8:0] IPU1_IRQ_69 rw
0x840 CTRL_CORE_IPU1_IRQ_71_72 reset 0x760077
  [24:16] IPU1_IRQ_72 rw, [8:0] IPU1_IRQ_71 rw
0x844 CTRL_CORE_IPU1_IRQ_73_74 reset 0x490048
  [24:16] IPU1_IRQ_74 rw, [8:0] IPU1_IRQ_73 rw
0x848 CTRL_CORE_IPU1_IRQ_75_76 reset 0x570075
  [24:16] IPU1_IRQ_76 rw, [8:0] IPU1_IRQ_75 rw
0x84C CTRL_CORE_IPU1_IRQ_77_78 reset 0x3E0058
  [24:16] IPU1_IRQ_78 rw, [8:0] IPU1_IRQ_77 rw
0x850 CTRL_CORE_IPU1_IRQ_79_80 reset 0x3F
  [8:0] IPU1_IRQ_79 rw
0x854 CTRL_CORE_IPU2_IRQ_23_24 reset 0x300014
  [24:16] IPU2_IRQ_24 rw, [8:0] IPU2_IRQ_23 rw
0x858 CTRL_CORE_IPU2_IRQ_25_26 reset 0x600000
  [24:16] IPU2_IRQ_26 rw, [8:0] IPU2_IRQ_25 rw
0x85C CTRL_CORE_IPU2_IRQ_27_28 reset 0x7F007E
  [24:16] IPU2_IRQ_28 rw, [8:0] IPU2_IRQ_27 rw
0x860 CTRL_CORE_IPU2_IRQ_29_30 reset 0x810080
  [24:16] IPU2_IRQ_30 rw, [8:0] IPU2_IRQ_29 rw
0x864 CTRL_CORE_IPU2_IRQ_31_32 reset 0x130082
  [24:16] IPU2_IRQ_32 rw, [8:0] IPU2_IRQ_31 rw
0x868 CTRL_CORE_IPU2_IRQ_33_34 reset 0x70083
  [24:16] IPU2_IRQ_34 rw, [8:0] IPU2_IRQ_33 rw
0x86C CTRL_CORE_IPU2_IRQ_35_36 reset 0x90008
  [24:16] IPU2_IRQ_36 rw, [8:0] IPU2_IRQ_35 rw
0x870 CTRL_CORE_IPU2_IRQ_37_38 reset 0x84000A
  [24:16] IPU2_IRQ_38 rw, [8:0] IPU2_IRQ_37 rw
0x874 CTRL_CORE_IPU2_IRQ_39_40 reset 0x630062
  [24:16] IPU2_IRQ_40 rw, [8:0] IPU2_IRQ_39 rw
0x878 CTRL_CORE_IPU2_IRQ_41_42 reset 0x340033
  [24:16] IPU2_IRQ_42 rw, [8:0] IPU2_IRQ_41 rw
0x87C CTRL_CORE_IPU2_IRQ_43_44 reset 0x390038
  [24:16] IPU2_IRQ_44 rw, [8:0] IPU2_IRQ_43 rw
0x880 CTRL_CORE_IPU2_IRQ_45_46 reset 0x50045
  [24:16] IPU2_IRQ_46 rw, [8:0] IPU2_IRQ_45 rw
0x884 CTRL_CORE_IPU2_IRQ_47_48 reset 0xE0085
  [24:16] IPU2_IRQ_48 rw, [8:0] IPU2_IRQ_47 rw
0x888 CTRL_CORE_IPU2_IRQ_49_50 reset 0x860042
  [24:16] IPU2_IRQ_50 rw, [8:0] IPU2_IRQ_49 rw
0x88C CTRL_CORE_IPU2_IRQ_51_52 reset 0x190018
  [24:16] IPU2_IRQ_52 rw, [8:0] IPU2_IRQ_51 rw
0x890 CTRL_CORE_IPU2_IRQ_53_54 reset 0x230022
  [24:16] IPU2_IRQ_54 rw, [8:0] IPU2_IRQ_53 rw
0x894 CTRL_CORE_IPU2_IRQ_55_56 reset 0x2A0028
  [24:16] IPU2_IRQ_56 rw, [8:0] IPU2_IRQ_55 rw
0x898 CTRL_CORE_IPU2_IRQ_57_58 reset 0x3D003C
  [24:16] IPU2_IRQ_58 rw, [8:0] IPU2_IRQ_57 rw
0x89C CTRL_CORE_IPU2_IRQ_59_60 reset 0x32
  [24:16] IPU2_IRQ_60 rw, [8:0] IPU2_IRQ_59 rw
0x8A0 CTRL_CORE_IPU2_IRQ_61_62 reset 0x160000
  [24:16] IPU2_IRQ_62 rw, [8:0] IPU2_IRQ_61 rw
0x8A4 CTRL_CORE_IPU2_IRQ_63_64 reset 0x6C0053
  [24:16] IPU2_IRQ_64 rw, [8:0] IPU2_IRQ_63 rw
0x8A8 CTRL_CORE_IPU2_IRQ_65_66 reset 0x4E0078
  [24:16] IPU2_IRQ_66 rw, [8:0] IPU2_IRQ_65 rw
0x8AC CTRL_CORE_IPU2_IRQ_67_68 reset 0x590051
  [24:16] IPU2_IRQ_68 rw, [8:0] IPU2_IRQ_67 rw
0x8B0 CTRL_CORE_IPU2_IRQ_69_70
  [24:16] IPU2_IRQ_70 rw, [8:0] IPU2_IRQ_69 rw
0x8B4 CTRL_CORE_IPU2_IRQ_71_72 reset 0x760077
  [24:16] IPU2_IRQ_72 rw, [8:0] IPU2_IRQ_71 rw
0x8B8 CTRL_CORE_IPU2_IRQ_73_74 reset 0x490048
  [24:16] IPU2_IRQ_74 rw, [8:0] IPU2_IRQ_73 rw
0x8BC CTRL_CORE_IPU2_IRQ_75_76 reset 0x570075
  [24:16] IPU2_IRQ_76 rw, [8:0] IPU2_IRQ_75 rw
0x8C0 CTRL_CORE_IPU2_IRQ_77_78 reset 0x3E0058
  [24:16] IPU2_IRQ_78 rw, [8:0] IPU2_IRQ_77 rw
0x8C4 CTRL_CORE_IPU2_IRQ_79_80 reset 0x3F
  [8:0] IPU2_IRQ_79 rw
0x8C8 CTRL_CORE_PRUSS1_IRQ_32_33 reset 0x20001
  [24:16] PRUSS1_IRQ_33 rw, [8:0] PRUSS1_IRQ_32 rw
0x8CC CTRL_CORE_PRUSS1_IRQ_34_35 reset 0x40003
  [24:16] PRUSS1_IRQ_35 rw, [8:0] PRUSS1_IRQ_34 rw
0x8D0 CTRL_CORE_PRUSS1_IRQ_36_37 reset 0x60005
  [24:16] PRUSS1_IRQ_37 rw, [8:0] PRUSS1_IRQ_36 rw
0x8D4 CTRL_CORE_PRUSS1_IRQ_38_39 reset 0x80007
  [24:16] PRUSS1_IRQ_39 rw, [8:0] PRUSS1_IRQ_38 rw
0x8D8 CTRL_CORE_PRUSS1_IRQ_40_41 reset 0xA0009
  [24:16] PRUSS1_IRQ_41 rw, [8:0] PRUSS1_IRQ_40 rw
0x8DC CTRL_CORE_PRUSS1_IRQ_42_43 reset 0xC000B
  [24:16] PRUSS1_IRQ_43 rw, [8:0] PRUSS1_IRQ_42 rw
0x8E0 CTRL_CORE_PRUSS1_IRQ_44_45 reset 0xE000D
  [24:16] PRUSS1_IRQ_45 rw, [8:0] PRUSS1_IRQ_44 rw
0x8E4 CTRL_CORE_PRUSS1_IRQ_46_47 reset 0x10000F
  [24:16] PRUSS1_IRQ_47 rw, [8:0] PRUSS1_IRQ_46 rw
0x8E8 CTRL_CORE_PRUSS1_IRQ_48_49 reset 0x120011
  [24:16] PRUSS1_IRQ_49 rw, [8:0] PRUSS1_IRQ_48 rw
0x8EC CTRL_CORE_PRUSS1_IRQ_50_51 reset 0x140013
  [24:16] PRUSS1_IRQ_51 rw, [8:0] PRUSS1_IRQ_50 rw
0x8F0 CTRL_CORE_PRUSS1_IRQ_52_53 reset 0x160015
  [24:16] PRUSS1_IRQ_53 rw, [8:0] PRUSS1_IRQ_52 rw
0x8F4 CTRL_CORE_PRUSS1_IRQ_54_55 reset 0x180017
  [24:16] PRUSS1_IRQ_55 rw, [8:0] PRUSS1_IRQ_54 rw
0x8F8 CTRL_CORE_PRUSS1_IRQ_56_57 reset 0x1A0019
  [24:16] PRUSS1_IRQ_57 rw, [8:0] PRUSS1_IRQ_56 rw
0x8FC CTRL_CORE_PRUSS1_IRQ_58_59 reset 0x1C001B
  [24:16] PRUSS1_IRQ_59 rw, [8:0] PRUSS1_IRQ_58 rw
0x900 CTRL_CORE_PRUSS1_IRQ_60_61 reset 0x1E001D
  [24:16] PRUSS1_IRQ_61 rw, [8:0] PRUSS1_IRQ_60 rw
0x904 CTRL_CORE_PRUSS1_IRQ_62_63 reset 0x20001F
  [24:16] PRUSS1_IRQ_63 rw, [8:0] PRUSS1_IRQ_62 rw
0x908 CTRL_CORE_PRUSS2_IRQ_32_33 reset 0x20001
  [24:16] PRUSS2_IRQ_33 rw, [8:0] PRUSS2_IRQ_32 rw
0x90C CTRL_CORE_PRUSS2_IRQ_34_35 reset 0x40003
  [24:16] PRUSS2_IRQ_35 rw, [8:0] PRUSS2_IRQ_34 rw
0x910 CTRL_CORE_PRUSS2_IRQ_36_37 reset 0x60005
  [24:16] PRUSS2_IRQ_37 rw, [8:0] PRUSS2_IRQ_36 rw
0x914 CTRL_CORE_PRUSS2_IRQ_38_39 reset 0x80007
  [24:16] PRUSS2_IRQ_39 rw, [8:0] PRUSS2_IRQ_38 rw
0x918 CTRL_CORE_PRUSS2_IRQ_40_41 reset 0xA0009
  [24:16] PRUSS2_IRQ_41 rw, [8:0] PRUSS2_IRQ_40 rw
0x91C CTRL_CORE_PRUSS2_IRQ_42_43 reset 0xC000B
  [24:16] PRUSS2_IRQ_43 rw, [8:0] PRUSS2_IRQ_42 rw
0x920 CTRL_CORE_PRUSS2_IRQ_44_45 reset 0xE000D
  [24:16] PRUSS2_IRQ_45 rw, [8:0] PRUSS2_IRQ_44 rw
0x924 CTRL_CORE_PRUSS2_IRQ_46_47 reset 0x10000F
  [24:16] PRUSS2_IRQ_47 rw, [8:0] PRUSS2_IRQ_46 rw
0x928 CTRL_CORE_PRUSS2_IRQ_48_49 reset 0x120011
  [24:16] PRUSS2_IRQ_49 rw, [8:0] PRUSS2_IRQ_48 rw
0x92C CTRL_CORE_PRUSS2_IRQ_50_51 reset 0x140013
  [24:16] PRUSS2_IRQ_51 rw, [8:0] PRUSS2_IRQ_50 rw
0x930 CTRL_CORE_PRUSS2_IRQ_52_53 reset 0x160015
  [24:16] PRUSS2_IRQ_53 rw, [8:0] PRUSS2_IRQ_52 rw
0x934 CTRL_CORE_PRUSS2_IRQ_54_55 reset 0x180017
  [24:16] PRUSS2_IRQ_55 rw, [8:0] PRUSS2_IRQ_54 rw
0x938 CTRL_CORE_PRUSS2_IRQ_56_57 reset 0x1A0019
  [24:16] PRUSS2_IRQ_57 rw, [8:0] PRUSS2_IRQ_56 rw
0x93C CTRL_CORE_PRUSS2_IRQ_58_59 reset 0x1C001B
  [24:16] PRUSS2_IRQ_59 rw, [8:0] PRUSS2_IRQ_58 rw
0x940 CTRL_CORE_PRUSS2_IRQ_60_61 reset 0x1E001D
  [24:16] PRUSS2_IRQ_61 rw, [8:0] PRUSS2_IRQ_60 rw
0x944 CTRL_CORE_PRUSS2_IRQ_62_63 reset 0x20001F
  [24:16] PRUSS2_IRQ_63 rw, [8:0] PRUSS2_IRQ_62 rw
0x948 CTRL_CORE_DSP1_IRQ_32_33 reset 0x20001
  [24:16] DSP1_IRQ_33 rw, [8:0] DSP1_IRQ_32 rw
0x94C CTRL_CORE_DSP1_IRQ_34_35 reset 0x40003
  [24:16] DSP1_IRQ_35 rw, [8:0] DSP1_IRQ_34 rw
0x950 CTRL_CORE_DSP1_IRQ_36_37 reset 0x60005
  [24:16] DSP1_IRQ_37 rw, [8:0] DSP1_IRQ_36 rw
0x954 CTRL_CORE_DSP1_IRQ_38_39 reset 0x80007
  [24:16] DSP1_IRQ_39 rw, [8:0] DSP1_IRQ_38 rw
0x958 CTRL_CORE_DSP1_IRQ_40_41 reset 0xA0009
  [24:16] DSP1_IRQ_41 rw, [8:0] DSP1_IRQ_40 rw
0x95C CTRL_CORE_DSP1_IRQ_42_43 reset 0xC000B
  [24:16] DSP1_IRQ_43 rw, [8:0] DSP1_IRQ_42 rw
0x960 CTRL_CORE_DSP1_IRQ_44_45 reset 0xE000D
  [24:16] DSP1_IRQ_45 rw, [8:0] DSP1_IRQ_44 rw
0x964 CTRL_CORE_DSP1_IRQ_46_47 reset 0x10000F
  [24:16] DSP1_IRQ_47 rw, [8:0] DSP1_IRQ_46 rw
0x968 CTRL_CORE_DSP1_IRQ_48_49 reset 0x120011
  [24:16] DSP1_IRQ_49 rw, [8:0] DSP1_IRQ_48 rw
0x96C CTRL_CORE_DSP1_IRQ_50_51 reset 0x140013
  [24:16] DSP1_IRQ_51 rw, [8:0] DSP1_IRQ_50 rw
0x970 CTRL_CORE_DSP1_IRQ_52_53 reset 0x160015
  [24:16] DSP1_IRQ_53 rw, [8:0] DSP1_IRQ_52 rw
0x974 CTRL_CORE_DSP1_IRQ_54_55 reset 0x180017
  [24:16] DSP1_IRQ_55 rw, [8:0] DSP1_IRQ_54 rw
0x978 CTRL_CORE_DSP1_IRQ_56_57 reset 0x1A0019
  [24:16] DSP1_IRQ_57 rw, [8:0] DSP1_IRQ_56 rw
0x97C CTRL_CORE_DSP1_IRQ_58_59 reset 0x1C001B
  [24:16] DSP1_IRQ_59 rw, [8:0] DSP1_IRQ_58 rw
0x980 CTRL_CORE_DSP1_IRQ_60_61 reset 0x1E001D
  [24:16] DSP1_IRQ_61 rw, [8:0] DSP1_IRQ_60 rw
0x984 CTRL_CORE_DSP1_IRQ_62_63 reset 0x20001F
  [24:16] DSP1_IRQ_63 rw, [8:0] DSP1_IRQ_62 rw
0x988 CTRL_CORE_DSP1_IRQ_64_65 reset 0x220021
  [24:16] DSP1_IRQ_65 rw, [8:0] DSP1_IRQ_64 rw
0x98C CTRL_CORE_DSP1_IRQ_66_67 reset 0x240023
  [24:16] DSP1_IRQ_67 rw, [8:0] DSP1_IRQ_66 rw
0x990 CTRL_CORE_DSP1_IRQ_68_69 reset 0x260025
  [24:16] DSP1_IRQ_69 rw, [8:0] DSP1_IRQ_68 rw
0x994 CTRL_CORE_DSP1_IRQ_70_71 reset 0x280027
  [24:16] DSP1_IRQ_71 rw, [8:0] DSP1_IRQ_70 rw
0x998 CTRL_CORE_DSP1_IRQ_72_73 reset 0x2A0029
  [24:16] DSP1_IRQ_73 rw, [8:0] DSP1_IRQ_72 rw
